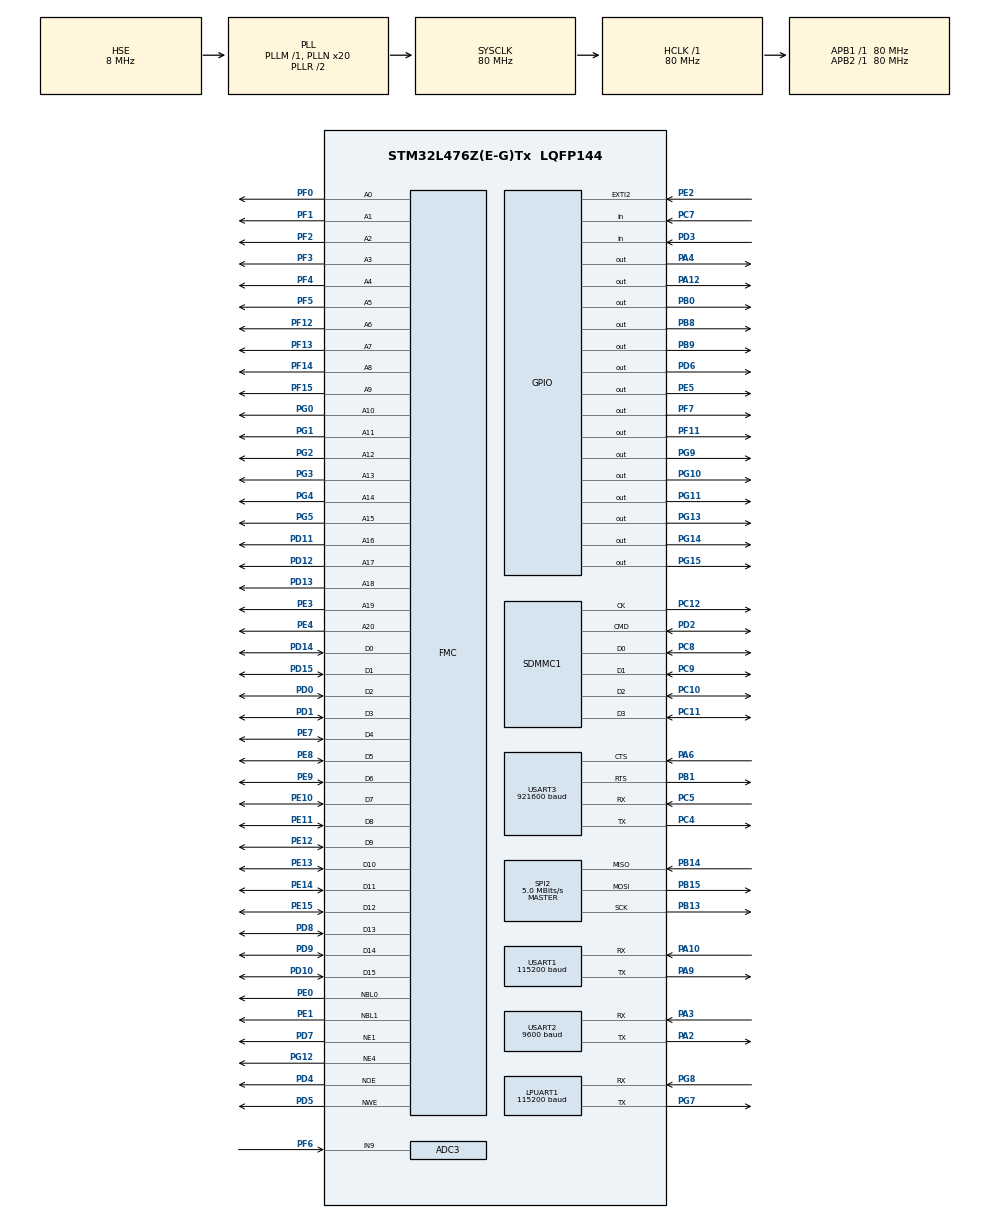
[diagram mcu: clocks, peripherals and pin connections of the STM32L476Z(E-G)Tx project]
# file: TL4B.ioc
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ADC3.Channel-3\#ChannelRegularConversion=ADC_CHANNEL_9
ADC3.ClockPrescaler=ADC_CLOCK_ASYNC_DIV4
ADC3.DataAlign=ADC_DATAALIGN_RIGHT
ADC3.NbrOfConversionFlag=1
ADC3.OffsetNumber-3\#ChannelRegularConversion=ADC_OFFSET_NONE
ADC3.Rank-3\#ChannelRegularConversion=1
ADC3.Resolution=ADC_RESOLUTION_10B
ADC3.SamplingTime-3\#ChannelRegularConversion=ADC_SAMPLETIME_2CYCLES_5
Dma.Request0=USART3_RX
Dma.USART3_RX.0.Direction=DMA_PERIPH_TO_MEMORY
Dma.USART3_RX.0.Instance=DMA1_Channel3
Dma.USART3_RX.0.MemDataAlignment=DMA_MDATAALIGN_BYTE
Dma.USART3_RX.0.MemInc=DMA_MINC_ENABLE
Dma.USART3_RX.0.Mode=DMA_NORMAL
Dma.USART3_RX.0.PeriphDataAlignment=DMA_PDATAALIGN_BYTE
Dma.USART3_RX.0.PeriphInc=DMA_PINC_DISABLE
Dma.USART3_RX.0.Priority=DMA_PRIORITY_LOW
FATFS.BSP.number=1
FATFS.USE_DMA_CODE_SD=0
FATFS._CODE_PAGE=936
FATFS._FS_MINIMIZE=0
FATFS._MAX_SS=4096
FATFS._USE_LFN=2
FATFS0.BSP.STBoard=false
FATFS0.BSP.api=Unknown
FATFS0.BSP.i2caddr=0
FATFS0.BSP.instance=PC7
FATFS0.BSP.ip=GPIO
FATFS0.BSP.mode=Input
FATFS0.BSP.name=Detect_SDIO
FATFS0.BSP.solution=PC7
FMC.WriteOperation1=FMC_WRITE_OPERATION_ENABLE
FMC.WriteOperation2=FMC_WRITE_OPERATION_ENABLE
IWDG.Prescaler=IWDG_PRESCALER_32
LPUART1.BaudRate=115200
LPUART1.WordLength=UART_WORDLENGTH_8B
Mcu.Family=STM32L4
Mcu.Name=STM32L476Z(E-G)Tx
Mcu.Package=LQFP144
NVIC.DMA1_Channel3_IRQn=true\:0\:0\:false\:false\:true\:false\:true
NVIC.EXTI2_IRQn=true\:0\:0\:false\:false\:true\:true\:true
NVIC.LPUART1_IRQn=true\:0\:0\:false\:false\:true\:true\:true
NVIC.PriorityGroup=NVIC_PRIORITYGROUP_4
NVIC.RTC_WKUP_IRQn=true\:0\:0\:false\:false\:true\:true\:true
NVIC.SDMMC1_IRQn=true\:0\:0\:false\:false\:true\:true\:true
NVIC.USART1_IRQn=true\:0\:0\:false\:false\:true\:true\:true
NVIC.USART2_IRQn=true\:0\:0\:false\:false\:true\:true\:true
NVIC.USART3_IRQn=true\:0\:0\:false\:false\:true\:true\:true
PA10.Mode=Asynchronous
PA10.Signal=USART1_RX
PA12.Signal=GPIO_Output
PA2.Mode=Asynchronous
PA2.Signal=USART2_TX
PA3.Mode=Asynchronous
PA3.Signal=USART2_RX
PA4.Signal=GPIO_Output
PA6.Mode=CTS_RTS
PA6.Signal=USART3_CTS
PA9.Mode=Asynchronous
PA9.Signal=USART1_TX
PB0.Signal=GPIO_Output
PB1.Mode=CTS_RTS
PB1.Signal=USART3_RTS
PB13.Mode=Full_Duplex_Master
PB13.Signal=SPI2_SCK
PB14.Mode=Full_Duplex_Master
PB14.Signal=SPI2_MISO
PB15.Mode=Full_Duplex_Master
PB15.Signal=SPI2_MOSI
PB8.Signal=GPIO_Output
PB9.Signal=GPIO_Output
PC10.Mode=SD_4_bits_Wide_bus
PC10.Signal=SDMMC1_D2
PC11.Mode=SD_4_bits_Wide_bus
PC11.Signal=SDMMC1_D3
PC12.Mode=SD_4_bits_Wide_bus
PC12.Signal=SDMMC1_CK
PC14-OSC32_IN\ (PC14).Mode=LSE-External-Oscillator
PC14-OSC32_IN\ (PC14).Signal=RCC_OSC32_IN
PC15-OSC32_OUT\ (PC15).Mode=LSE-External-Oscillator
PC15-OSC32_OUT\ (PC15).Signal=RCC_OSC32_OUT
PC4.Mode=Asynchronous
PC4.Signal=USART3_TX
PC5.Mode=Asynchronous
PC5.Signal=USART3_RX
PC7.Signal=GPIO_Input
PC8.Mode=SD_4_bits_Wide_bus
PC8.Signal=SDMMC1_D0
PC9.Mode=SD_4_bits_Wide_bus
PC9.Signal=SDMMC1_D1
PD0.Signal=FMC_D2_DA2
PD1.Signal=FMC_D3_DA3
PD10.Signal=FMC_D15_DA15
PD11.Signal=FMC_A16_CLE
PD12.Signal=FMC_A17_ALE
PD13.Signal=FMC_A18
PD14.Signal=FMC_D0_DA0
PD15.Signal=FMC_D1_DA1
PD2.Mode=SD_4_bits_Wide_bus
PD2.Signal=SDMMC1_CMD
PD3.Signal=GPIO_Input
PD4.Signal=FMC_NOE
PD5.Signal=FMC_NWE
PD6.Signal=GPIO_Output
PD7.Mode=NorPsramChipSelect1_1
PD7.Signal=FMC_NE1
PD8.Signal=FMC_D13_DA13
PD9.Signal=FMC_D14_DA14
PE0.Signal=FMC_NBL0
PE1.Signal=FMC_NBL1
PE10.Signal=FMC_D7_DA7
PE11.Signal=FMC_D8_DA8
PE12.Signal=FMC_D9_DA9
PE13.Signal=FMC_D10_DA10
PE14.Signal=FMC_D11_DA11
PE15.Signal=FMC_D12_DA12
PE2.Signal=GPXTI2
PE3.Signal=FMC_A19
PE4.Signal=FMC_A20
PE5.Signal=GPIO_Output
PE7.Signal=FMC_D4_DA4
PE8.Signal=FMC_D5_DA5
PE9.Signal=FMC_D6_DA6
PF0.Signal=FMC_A0
PF1.Signal=FMC_A1
PF11.Signal=GPIO_Output
PF12.Signal=FMC_A6
PF13.Signal=FMC_A7
PF14.Signal=FMC_A8
PF15.Signal=FMC_A9
PF2.Signal=FMC_A2
PF3.Signal=FMC_A3
PF4.Signal=FMC_A4
PF5.Signal=FMC_A5
PF6.Signal=SharedAnalog_PF6
PF7.Signal=GPIO_Output
PG0.Signal=FMC_A10
PG1.Signal=FMC_A11
PG10.Signal=GPIO_Output
PG11.Signal=GPIO_Output
PG12.Mode=NorPsramChipSelect4_2
PG12.Signal=FMC_NE4
PG13.Signal=GPIO_Output
PG14.Signal=GPIO_Output
PG15.Signal=GPIO_Output
PG2.Signal=FMC_A12
PG3.Signal=FMC_A13
PG4.Signal=FMC_A14
PG5.Signal=FMC_A15
PG7.Mode=Asynchronous
PG7.Signal=LPUART1_TX
PG8.Mode=Asynchronous
PG8.Signal=LPUART1_RX
PG9.Signal=GPIO_Output
PH0-OSC_IN\ (PH0).Mode=HSE-External-Oscillator
PH0-OSC_IN\ (PH0).Signal=RCC_OSC_IN
PH1-OSC_OUT\ (PH1).Mode=HSE-External-Oscillator
PH1-OSC_OUT\ (PH1).Signal=RCC_OSC_OUT
ProjectManager.HeapSize=0x200
ProjectManager.StackSize=0x400
ProjectManager.TargetToolchain=MDK-ARM V5
RCC.ADCFreq_Value=32000000
RCC.AHBFreq_Value=80000000
RCC.APB1Freq_Value=80000000
RCC.APB1TimFreq_Value=80000000
RCC.APB2Freq_Value=80000000
RCC.APB2TimFreq_Value=80000000
RCC.CortexFreq_Value=80000000
RCC.HCLKFreq_Value=80000000
RCC.HSE_VALUE=8000000
RCC.HSI_VALUE=16000000
RCC.MSI_VALUE=4000000
RCC.PLLN=20
RCC.PLLSourceVirtual=RCC_PLLSOURCE_HSE
RCC.RTCClockSelection=RCC_RTCCLKSOURCE_LSE
RCC.SYSCLKFreq_VALUE=80000000
RCC.SYSCLKSource=RCC_SYSCLKSOURCE_PLLCLK
RCC.USBFreq_Value=32000000
RCC.VCOOutputFreq_Value=160000000
RTC.WakeUpClock-WakeUp=RTC_WAKEUPCLOCK_CK_SPRE_16BITS
SDMMC1.ClockDiv=16
SH.FMC_A0.0=FMC_A0,21b-a1
SH.FMC_A0.1=FMC_A0,1b-a2
SH.FMC_A1.0=FMC_A1,21b-a1
SH.FMC_A10.0=FMC_A10,21b-a1
SH.FMC_A11.0=FMC_A11,21b-a1
SH.FMC_A12.0=FMC_A12,21b-a1
SH.FMC_A13.0=FMC_A13,21b-a1
SH.FMC_A14.0=FMC_A14,21b-a1
SH.FMC_A15.0=FMC_A15,21b-a1
SH.FMC_A16_CLE.0=FMC_A16,21b-a1
SH.FMC_A17_ALE.0=FMC_A17,21b-a1
SH.FMC_A18.0=FMC_A18,21b-a1
SH.FMC_A19.0=FMC_A19,21b-a1
SH.FMC_A2.0=FMC_A2,21b-a1
SH.FMC_A20.0=FMC_A20,21b-a1
SH.FMC_A3.0=FMC_A3,21b-a1
SH.FMC_A4.0=FMC_A4,21b-a1
SH.FMC_A5.0=FMC_A5,21b-a1
SH.FMC_A6.0=FMC_A6,21b-a1
SH.FMC_A7.0=FMC_A7,21b-a1
SH.FMC_A8.0=FMC_A8,21b-a1
SH.FMC_A9.0=FMC_A9,21b-a1
SH.FMC_D0_DA0.0=FMC_D0,16b-d1
SH.FMC_D0_DA0.1=FMC_D0,16b-d2
SH.FMC_D10_DA10.0=FMC_D10,16b-d1
SH.FMC_D10_DA10.1=FMC_D10,16b-d2
SH.FMC_D11_DA11.0=FMC_D11,16b-d1
SH.FMC_D11_DA11.1=FMC_D11,16b-d2
SH.FMC_D12_DA12.0=FMC_D12,16b-d1
SH.FMC_D12_DA12.1=FMC_D12,16b-d2
SH.FMC_D13_DA13.0=FMC_D13,16b-d1
SH.FMC_D13_DA13.1=FMC_D13,16b-d2
SH.FMC_D14_DA14.0=FMC_D14,16b-d1
SH.FMC_D14_DA14.1=FMC_D14,16b-d2
SH.FMC_D15_DA15.0=FMC_D15,16b-d1
SH.FMC_D15_DA15.1=FMC_D15,16b-d2
SH.FMC_D1_DA1.0=FMC_D1,16b-d1
SH.FMC_D1_DA1.1=FMC_D1,16b-d2
SH.FMC_D2_DA2.0=FMC_D2,16b-d1
SH.FMC_D2_DA2.1=FMC_D2,16b-d2
SH.FMC_D3_DA3.0=FMC_D3,16b-d1
SH.FMC_D3_DA3.1=FMC_D3,16b-d2
SH.FMC_D4_DA4.0=FMC_D4,16b-d1
SH.FMC_D4_DA4.1=FMC_D4,16b-d2
SH.FMC_D5_DA5.0=FMC_D5,16b-d1
SH.FMC_D5_DA5.1=FMC_D5,16b-d2
SH.FMC_D6_DA6.0=FMC_D6,16b-d1
SH.FMC_D6_DA6.1=FMC_D6,16b-d2
SH.FMC_D7_DA7.0=FMC_D7,16b-d1
SH.FMC_D7_DA7.1=FMC_D7,16b-d2
SH.FMC_D8_DA8.0=FMC_D8,16b-d1
SH.FMC_D8_DA8.1=FMC_D8,16b-d2
SH.FMC_D9_DA9.0=FMC_D9,16b-d1
SH.FMC_D9_DA9.1=FMC_D9,16b-d2
SH.FMC_NBL0.0=FMC_NBL0,2ByteEnable1
SH.FMC_NBL1.0=FMC_NBL1,2ByteEnable1
SH.FMC_NOE.0=FMC_NOE,Sram1
SH.FMC_NOE.1=FMC_NOE,Sram2
SH.FMC_NWE.0=FMC_NWE,Sram1
SH.FMC_NWE.1=FMC_NWE,Sram2
SH.SharedAnalog_PF6.0=GPIO_Analog
SH.SharedAnalog_PF6.1=ADC3_IN9,IN9-Single-Ended
SPI2.BaudRatePrescaler=SPI_BAUDRATEPRESCALER_16
SPI2.CalculateBaudRate=5.0 MBits/s
SPI2.DataSize=SPI_DATASIZE_8BIT
SPI2.Direction=SPI_DIRECTION_2LINES
SPI2.Mode=SPI_MODE_MASTER
SPI2.VirtualType=VM_MASTER
USART1.BaudRate=115200
USART1.VirtualMode-Asynchronous=VM_ASYNC
USART2.BaudRate=9600
USART2.VirtualMode-Asynchronous=VM_ASYNC
USART3.BaudRate=921600
USART3.VirtualMode-Asynchronous=VM_ASYNC
VP_FATFS_VS_SDIO.Mode=SDIO
VP_IWDG_VS_IWDG.Mode=IWDG_Activate
VP_RTC_VS_RTC_Activate.Mode=RTC_Enabled
VP_RTC_VS_RTC_WakeUp_intern.Mode=WakeUp
board=custom

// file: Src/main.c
/* USER CODE BEGIN Header */
/**
  ******************************************************************************
  * @file           : main.c
  * @brief          : Main program body
  ******************************************************************************
  * @attention
  *
  * <h2><center>&copy; Copyright (c) 2019 STMicroelectronics.
  * All rights reserved.</center></h2>
  *
  * This software component is licensed by ST under BSD 3-Clause license,
  * the "License"; You may not use this file except in compliance with the
  * License. You may obtain a copy of the License at:
  *                        opensource.org/licenses/BSD-3-Clause
  *
  ******************************************************************************
  */
/* USER CODE END Header */

#include "main.h"
#include "adc.h"
#include "dma.h"
#include "fatfs.h"
#include "iwdg.h"
#include "usart.h"
#include "rtc.h"
#include "sdmmc.h"
#include "spi.h"
#include "gpio.h"
#include "fmc.h"

void SystemClock_Config(void);

/* USER CODE BEGIN 0 */
void udelay_no_inv(int cnt);
void app_start(void);
void stop_test(void);
#include "power_ctrl.h"
void all_power_down(void);
#include <stdio.h>			//printf();
#include <string.h>			//�ַ�����
/* USER CODE END 0 */

int main(void)
{
  /* USER CODE BEGIN 1 */
	SCB->VTOR = FLASH_BASE | 0x8000;//����ƫ����
  /* USER CODE END 1 */

  /* MCU Configuration--------------------------------------------------------*/

  /* Reset of all peripherals, Initializes the Flash interface and the Systick. */
  HAL_Init();

  /* Configure the system clock */
  SystemClock_Config();

  /* Initialize all configured peripherals */
  MX_GPIO_Init();
  MX_DMA_Init();
  MX_USART1_UART_Init();
  MX_LPUART1_UART_Init();
  MX_USART3_UART_Init();
  MX_USART2_UART_Init();
  MX_ADC3_Init();
  MX_FMC_Init();
  MX_SDMMC1_SD_Init();
  MX_FATFS_Init();
  MX_SPI2_Init();
//  MX_IWDG_Init();
  MX_RTC_Init();

  /* Infinite loop */
  /* USER CODE BEGIN WHILE */
  while (1)
  {
//		printf("\r\ndev_start");//ndev_start
//		printf("mark001");

//		udelay_no_inv(0x01FfFfff);
//		stop_test();

//		HAL_IWDG_Refresh(&hiwdg);
  	app_start();
    /* USER CODE END WHILE */

  }
}

void SystemClock_Config(void)
{
  RCC_OscInitTypeDef RCC_OscInitStruct = {0};
  RCC_ClkInitTypeDef RCC_ClkInitStruct = {0};
  RCC_PeriphCLKInitTypeDef PeriphClkInit = {0};

  /** Configure LSE Drive Capability
  */
  HAL_PWR_EnableBkUpAccess();
  __HAL_RCC_LSEDRIVE_CONFIG(RCC_LSEDRIVE_LOW);
  /** Initializes the CPU, AHB and APB busses clocks
  */
  RCC_OscInitStruct.OscillatorType = RCC_OSCILLATORTYPE_LSI|RCC_OSCILLATORTYPE_HSE
                              |RCC_OSCILLATORTYPE_LSE;
  RCC_OscInitStruct.HSEState = RCC_HSE_ON;
  RCC_OscInitStruct.LSEState = RCC_LSE_ON;
  RCC_OscInitStruct.LSIState = RCC_LSI_ON;
  RCC_OscInitStruct.PLL.PLLState = RCC_PLL_ON;
  RCC_OscInitStruct.PLL.PLLSource = RCC_PLLSOURCE_HSE;
  RCC_OscInitStruct.PLL.PLLM = 1;
  RCC_OscInitStruct.PLL.PLLN = 20;
  RCC_OscInitStruct.PLL.PLLP = RCC_PLLP_DIV7;
  RCC_OscInitStruct.PLL.PLLQ = RCC_PLLQ_DIV2;
  RCC_OscInitStruct.PLL.PLLR = RCC_PLLR_DIV2;
  if (HAL_RCC_OscConfig(&RCC_OscInitStruct) != HAL_OK)
  {
    Error_Handler();
  }
  /** Initializes the CPU, AHB and APB busses clocks
  */
  RCC_ClkInitStruct.ClockType = RCC_CLOCKTYPE_HCLK|RCC_CLOCKTYPE_SYSCLK
                              |RCC_CLOCKTYPE_PCLK1|RCC_CLOCKTYPE_PCLK2;
  RCC_ClkInitStruct.SYSCLKSource = RCC_SYSCLKSOURCE_PLLCLK;
  RCC_ClkInitStruct.AHBCLKDivider = RCC_SYSCLK_DIV1;
  RCC_ClkInitStruct.APB1CLKDivider = RCC_HCLK_DIV1;
  RCC_ClkInitStruct.APB2CLKDivider = RCC_HCLK_DIV1;

  if (HAL_RCC_ClockConfig(&RCC_ClkInitStruct, FLASH_LATENCY_4) != HAL_OK)
  {
    Error_Handler();
  }
  PeriphClkInit.PeriphClockSelection = RCC_PERIPHCLK_RTC|RCC_PERIPHCLK_USART1
                              |RCC_PERIPHCLK_USART2|RCC_PERIPHCLK_USART3
                              |RCC_PERIPHCLK_LPUART1|RCC_PERIPHCLK_SDMMC1
                              |RCC_PERIPHCLK_ADC;
  PeriphClkInit.Usart1ClockSelection = RCC_USART1CLKSOURCE_PCLK2;
  PeriphClkInit.Usart2ClockSelection = RCC_USART2CLKSOURCE_PCLK1;
  PeriphClkInit.Usart3ClockSelection = RCC_USART3CLKSOURCE_PCLK1;
  PeriphClkInit.Lpuart1ClockSelection = RCC_LPUART1CLKSOURCE_PCLK1;
  PeriphClkInit.AdcClockSelection = RCC_ADCCLKSOURCE_PLLSAI1;
  PeriphClkInit.RTCClockSelection = RCC_RTCCLKSOURCE_LSE;
  PeriphClkInit.Sdmmc1ClockSelection = RCC_SDMMC1CLKSOURCE_PLLSAI1;
  PeriphClkInit.PLLSAI1.PLLSAI1Source = RCC_PLLSOURCE_HSE;
  PeriphClkInit.PLLSAI1.PLLSAI1M = 1;
  PeriphClkInit.PLLSAI1.PLLSAI1N = 8;
  PeriphClkInit.PLLSAI1.PLLSAI1P = RCC_PLLP_DIV7;
  PeriphClkInit.PLLSAI1.PLLSAI1Q = RCC_PLLQ_DIV2;
  PeriphClkInit.PLLSAI1.PLLSAI1R = RCC_PLLR_DIV2;
  PeriphClkInit.PLLSAI1.PLLSAI1ClockOut = RCC_PLLSAI1_48M2CLK|RCC_PLLSAI1_ADC1CLK;
  if (HAL_RCCEx_PeriphCLKConfig(&PeriphClkInit) != HAL_OK)
  {
    Error_Handler();
  }
  /** Configure the main internal regulator output voltage
  */
  if (HAL_PWREx_ControlVoltageScaling(PWR_REGULATOR_VOLTAGE_SCALE1) != HAL_OK)
  {
    Error_Handler();
  }
}

void Error_Handler(void)
{
}

/************************ (C) COPYRIGHT STMicroelectronics *****END OF FILE****/
